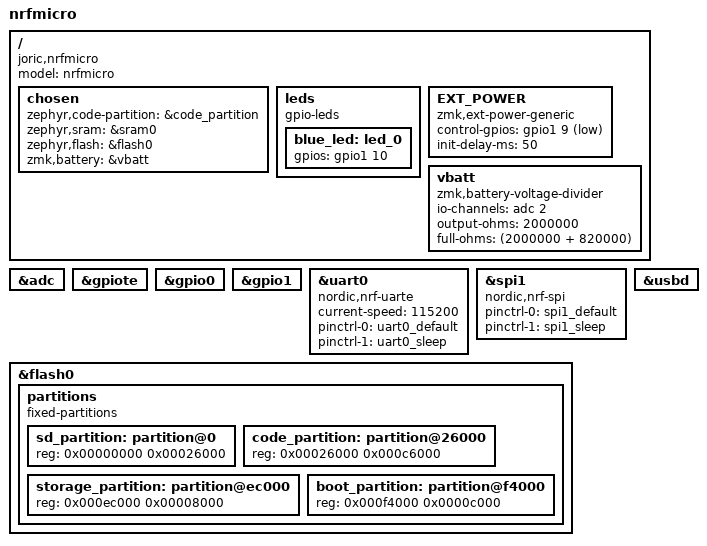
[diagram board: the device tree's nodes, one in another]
// This file was generated from a template. Edit it to match your keyboard.
// See https://docs.zephyrproject.org/4.1.0/hardware/porting/board_porting.html
// and https://zmk.dev/docs/development/hardware-integration/new-shield for more
// instructions.

/dts-v1/;
#include <nordic/nrf52840_qiaa.dtsi>

#include "ewt73-pins.dtsi"
#include "ewt73-pinctrl.dtsi"

/ {
    model = "nrfmicro";
    compatible = "joric,nrfmicro";

    chosen {
        zephyr,code-partition = &code_partition;
        zephyr,sram = &sram0;
        zephyr,flash = &flash0;
        zmk,battery = &vbatt;
    };

    leds {
        compatible = "gpio-leds";
        blue_led: led_0 {
            gpios = <&gpio1 10 GPIO_ACTIVE_HIGH>;
        };
    };

    // Node name must match original "EXT_POWER" label to preserve user settings.
    EXT_POWER {
        compatible = "zmk,ext-power-generic";
        control-gpios = <&gpio1 9 GPIO_ACTIVE_LOW>;
        init-delay-ms = <50>;
    };

    vbatt: vbatt {
        compatible = "zmk,battery-voltage-divider";
        io-channels = <&adc 2>;
        output-ohms = <2000000>;
        full-ohms = <(2000000 + 820000)>;
    };
};

// Uncomment this to switch from the LDO to the DC/DC regulator on REG0.
// Do not enable the DC/DC regulator without an LC filter connected to the DCCH
// pin, or the keyboard will not boot until an LC filter is connected.
// &reg0 {
//     status = "okay";
// };

// Uncomment this to switch from the LDO to the DC/DC regulator on REG1.
// Do not enable the DC/DC regulator without an LC filter connected to the DCC
// pin, or the keyboard will not boot until an LC filter is connected.
// &reg1 {
//     regulator-initial-mode = <NRF5X_REG_MODE_DCDC>;
// };

&adc {
    status = "okay";
};

&gpiote {
    status = "okay";
};

&gpio0 {
    status = "okay";
};

&gpio1 {
    status = "okay";
};

&uart0 {
    compatible = "nordic,nrf-uarte";
    current-speed = <115200>;
    pinctrl-0 = <&uart0_default>;
    pinctrl-1 = <&uart0_sleep>;
    pinctrl-names = "default", "sleep";
};

&spi1 {
    compatible = "nordic,nrf-spi";
    pinctrl-0 = <&spi1_default>;
    pinctrl-1 = <&spi1_sleep>;
    pinctrl-names = "default", "sleep";
};

// If you use the NFC pins as GPIOs, uncomment this. Otherwise, remove it.
// &uicr {
//     nfct-pins-as-gpios;
// };

zephyr_udc0: &usbd {
    status = "okay";
};

&flash0 {
    /*
     * For more information, see:
     * http://docs.zephyrproject.org/latest/devices/dts/flash_partitions.html
     */
    partitions {
        compatible = "fixed-partitions";
        #address-cells = <1>;
        #size-cells = <1>;

        sd_partition: partition@0 {
            reg = <0x00000000 0x00026000>;
        };
        code_partition: partition@26000 {
            reg = <0x00026000 0x000c6000>;
        };

        /*
         * The flash starting at 0x000ec000 and ending at
         * 0x000f3fff is reserved for use by the application.
         */

        /*
         * Storage partition will be used by FCB/LittleFS/NVS
         * if enabled.
         */
        storage_partition: partition@ec000 {
            reg = <0x000ec000 0x00008000>;
        };

        boot_partition: partition@f4000 {
            reg = <0x000f4000 0x0000c000>;
        };
    };
};
